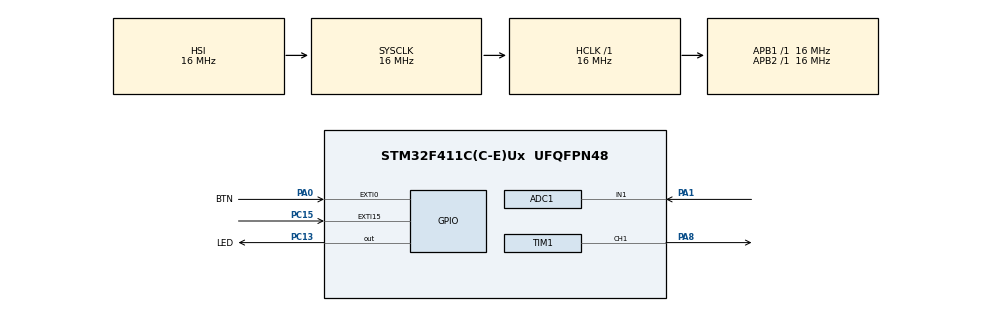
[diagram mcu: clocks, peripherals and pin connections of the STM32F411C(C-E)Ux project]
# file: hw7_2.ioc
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ADC1.Channel-2\#ChannelRegularConversion=ADC_CHANNEL_1
ADC1.DMAContinuousRequests=ENABLE
ADC1.ExternalTrigConv=ADC_EXTERNALTRIGCONV_T2_TRGO
ADC1.NbrOfConversionFlag=1
ADC1.Rank-2\#ChannelRegularConversion=1
ADC1.SamplingTime-2\#ChannelRegularConversion=ADC_SAMPLETIME_3CYCLES
ADC1.master=1
Dma.ADC1.0.Direction=DMA_PERIPH_TO_MEMORY
Dma.ADC1.0.FIFOMode=DMA_FIFOMODE_DISABLE
Dma.ADC1.0.Instance=DMA2_Stream0
Dma.ADC1.0.MemDataAlignment=DMA_MDATAALIGN_HALFWORD
Dma.ADC1.0.MemInc=DMA_MINC_ENABLE
Dma.ADC1.0.Mode=DMA_CIRCULAR
Dma.ADC1.0.PeriphDataAlignment=DMA_PDATAALIGN_HALFWORD
Dma.ADC1.0.PeriphInc=DMA_PINC_DISABLE
Dma.ADC1.0.Priority=DMA_PRIORITY_LOW
Dma.Request0=ADC1
Dma.Request1=TIM1_CH1
Dma.TIM1_CH1.1.Direction=DMA_MEMORY_TO_PERIPH
Dma.TIM1_CH1.1.FIFOMode=DMA_FIFOMODE_DISABLE
Dma.TIM1_CH1.1.Instance=DMA2_Stream1
Dma.TIM1_CH1.1.MemDataAlignment=DMA_MDATAALIGN_HALFWORD
Dma.TIM1_CH1.1.MemInc=DMA_MINC_ENABLE
Dma.TIM1_CH1.1.Mode=DMA_CIRCULAR
Dma.TIM1_CH1.1.PeriphDataAlignment=DMA_PDATAALIGN_HALFWORD
Dma.TIM1_CH1.1.PeriphInc=DMA_PINC_DISABLE
Dma.TIM1_CH1.1.Priority=DMA_PRIORITY_LOW
Mcu.Family=STM32F4
Mcu.Name=STM32F411C(C-E)Ux
Mcu.Package=UFQFPN48
NVIC.DMA2_Stream0_IRQn=true\:0\:0\:false\:false\:true\:false\:true\:true
NVIC.DMA2_Stream1_IRQn=true\:0\:0\:false\:false\:true\:false\:true\:true
NVIC.EXTI0_IRQn=true\:0\:0\:false\:false\:true\:true\:true\:true
NVIC.PriorityGroup=NVIC_PRIORITYGROUP_4
PA0-WKUP.GPIO_Label=BTN
PA0-WKUP.GPIO_ModeDefaultEXTI=GPIO_MODE_IT_FALLING
PA0-WKUP.Signal=GPXTI0
PA1.Signal=ADCx_IN1
PA8.Signal=S_TIM1_CH1
PC13-ANTI_TAMP.GPIO_Label=LED
PC13-ANTI_TAMP.Signal=GPIO_Output
PC15-OSC32_OUT.Signal=GPXTI15
ProjectManager.HeapSize=0x200
ProjectManager.StackSize=0x400
ProjectManager.TargetToolchain=Makefile
RCC.AHBFreq_Value=16000000
RCC.APB1Freq_Value=16000000
RCC.APB2Freq_Value=16000000
RCC.CortexFreq_Value=16000000
RCC.HSE_VALUE=25000000
RCC.HSI_VALUE=16000000
RCC.LSE_VALUE=32768
RCC.SYSCLKFreq_VALUE=16000000
RCC.VCOOutputFreq_Value=192000000
SH.ADCx_IN1.0=ADC1_IN1,IN1
SH.S_TIM1_CH1.0=TIM1_CH1,PWM Generation1 CH1
TIM1.AutoReloadPreload=TIM_AUTORELOAD_PRELOAD_ENABLE
TIM1.Channel-PWM\ Generation1\ CH1=TIM_CHANNEL_1
TIM1.Period=3999
TIM1.Prescaler=3999
TIM2.AutoReloadPreload=TIM_AUTORELOAD_PRELOAD_ENABLE
TIM2.Period=3999
TIM2.Prescaler=3999
TIM2.TIM_MasterOutputTrigger=TIM_TRGO_UPDATE
TIM2.TIM_MasterSlaveMode=TIM_MASTERSLAVEMODE_DISABLE
VP_TIM2_VS_ClockSourceINT.Mode=Internal
board=custom

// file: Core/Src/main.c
/* USER CODE BEGIN Header */
/**
  ******************************************************************************
  * @file           : main.c
  * @brief          : Main program body
  ******************************************************************************
  * @attention
  *
  * Copyright (c) 2026 STMicroelectronics.
  * All rights reserved.
  *
  * This software is licensed under terms that can be found in the LICENSE file
  * in the root directory of this software component.
  * If no LICENSE file comes with this software, it is provided AS-IS.
  *
  ******************************************************************************
  */
/* USER CODE END Header */
#include "main.h"
#include "adc.h"
#include "dma.h"
#include "tim.h"
#include "gpio.h"

/* USER CODE BEGIN PV */
volatile uint16_t light[100] = { 0 };
/* USER CODE END PV */

void SystemClock_Config(void);

int main(void)
{

  /* MCU Configuration--------------------------------------------------------*/

  /* Reset of all peripherals, Initializes the Flash interface and the Systick. */
  HAL_Init();

  /* Configure the system clock */
  SystemClock_Config();

  /* Initialize all configured peripherals */
  MX_GPIO_Init();
  MX_DMA_Init();
  MX_ADC1_Init();
  MX_TIM1_Init();
  MX_TIM2_Init();
  /* USER CODE BEGIN 2 */
  HAL_TIM_Base_Start(&htim2);
  HAL_ADC_Start_DMA(&hadc1,(uint32_t*)light,100);

  HAL_Delay(500);
  HAL_TIM_PWM_Start_DMA(&htim1,TIM_CHANNEL_1, (uint32_t*)light, 100);
  /* USER CODE END 2 */

  /* Infinite loop */
  while (1)
  {

  }
}

void SystemClock_Config(void)
{
  RCC_OscInitTypeDef RCC_OscInitStruct = {0};
  RCC_ClkInitTypeDef RCC_ClkInitStruct = {0};

  /** Configure the main internal regulator output voltage
  */
  __HAL_RCC_PWR_CLK_ENABLE();
  __HAL_PWR_VOLTAGESCALING_CONFIG(PWR_REGULATOR_VOLTAGE_SCALE1);

  /** Initializes the RCC Oscillators according to the specified parameters
  * in the RCC_OscInitTypeDef structure.
  */
  RCC_OscInitStruct.OscillatorType = RCC_OSCILLATORTYPE_HSI;
  RCC_OscInitStruct.HSIState = RCC_HSI_ON;
  RCC_OscInitStruct.HSICalibrationValue = RCC_HSICALIBRATION_DEFAULT;
  RCC_OscInitStruct.PLL.PLLState = RCC_PLL_NONE;
  if (HAL_RCC_OscConfig(&RCC_OscInitStruct) != HAL_OK)
  {
    Error_Handler();
  }

  /** Initializes the CPU, AHB and APB buses clocks
  */
  RCC_ClkInitStruct.ClockType = RCC_CLOCKTYPE_HCLK|RCC_CLOCKTYPE_SYSCLK
                              |RCC_CLOCKTYPE_PCLK1|RCC_CLOCKTYPE_PCLK2;
  RCC_ClkInitStruct.SYSCLKSource = RCC_SYSCLKSOURCE_HSI;
  RCC_ClkInitStruct.AHBCLKDivider = RCC_SYSCLK_DIV1;
  RCC_ClkInitStruct.APB1CLKDivider = RCC_HCLK_DIV1;
  RCC_ClkInitStruct.APB2CLKDivider = RCC_HCLK_DIV1;

  if (HAL_RCC_ClockConfig(&RCC_ClkInitStruct, FLASH_LATENCY_0) != HAL_OK)
  {
    Error_Handler();
  }
}

void Error_Handler(void)
{
  __disable_irq();
  while (1)
  {
  }
}
